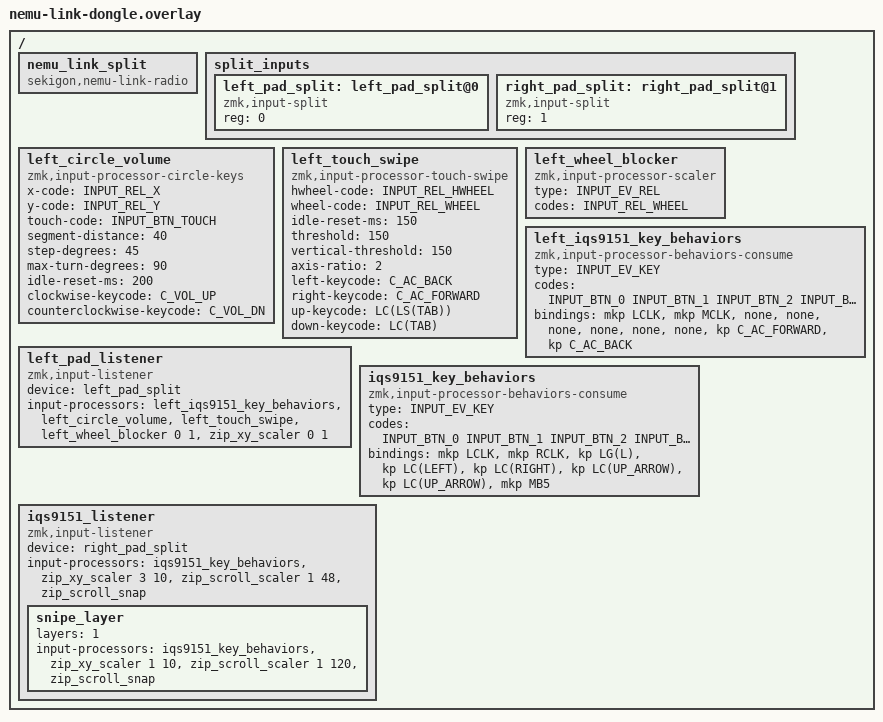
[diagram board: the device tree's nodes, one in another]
/*
 * nemu-link dongle (2.4GHz receiver / split central / USB HID).
 *
 * The dongle has no keys or pads of its own: both halves forward their key
 * positions and raw IQS9151 events, and everything that used to run on the
 * right (BLE central) half runs here: the keymap, combos, and every pad
 * listener / input processor below.
 */
#include <behaviors.dtsi>
#include <scroll-snap.dtsi>
#include <input/processors.dtsi>
#include <dt-bindings/zmk/input_transform.h>
#include <dt-bindings/zmk/keys.h>
#include <dt-bindings/zmk/pointing.h>
#include <zephyr/dt-bindings/input/input-event-codes.h>
#include "../../shields/nickey44a/nickey44a_layouts.dtsi"

/ {
    nemu_link_split {
        compatible = "sekigon,nemu-link-radio";
    };
};

/ {
    split_inputs {
        #address-cells = <1>;
        #size-cells = <0>;

        /* Left half (PERIPHERAL_ID 0) pad. */
        left_pad_split: left_pad_split@0 {
            compatible = "zmk,input-split";
            reg = <0>;
        };

        /* Right half (PERIPHERAL_ID 1) pad. */
        right_pad_split: right_pad_split@1 {
            compatible = "zmk,input-split";
            reg = <1>;
        };
    };

    /*
     * Left pad: one-finger circular motion changes the volume (clockwise =
     * up, 45 degrees per step). If the direction feels reversed on hardware,
     * swap the two keycodes.
     */
    left_circle_volume: left_circle_volume {
        compatible = "zmk,input-processor-circle-keys";
        #input-processor-cells = <0>;
        x-code = <INPUT_REL_X>;
        y-code = <INPUT_REL_Y>;
        /* IQS9151 has no TOUCH event; idle-reset-ms delimits strokes. */
        touch-code = <INPUT_BTN_TOUCH>;
        /* Tuned for IQS9151 raw counts; raise if jitter fires steps. */
        segment-distance = <40>;
        step-degrees = <45>;
        max-turn-degrees = <90>;
        idle-reset-ms = <200>;
        clockwise-keycode = <C_VOL_UP>;
        counterclockwise-keycode = <C_VOL_DN>;
    };

    /*
     * Left pad (IQS9151): one browser tab switch per two-finger up/down
     * swipe (Ctrl+Tab = next tab, Ctrl+Shift+Tab = previous tab). The
     * IQS9151 has no TOUCH event, so a WHEEL gap of idle-reset-ms starts a
     * new swipe. Horizontal Back/Forward comes from the driver's one-shot
     * 2F swipe (BTN_8/BTN_9) instead, since SCROLL_X is off on the left.
     * If the vertical direction is reversed on hardware, swap the keycodes.
     */
    left_touch_swipe: left_touch_swipe {
        compatible = "zmk,input-processor-touch-swipe";
        #input-processor-cells = <0>;
        hwheel-code = <INPUT_REL_HWHEEL>;
        wheel-code = <INPUT_REL_WHEEL>;
        idle-reset-ms = <150>;
        /* Raw IQS9151 centroid counts after the 50-count scroll start. */
        threshold = <150>;
        vertical-threshold = <150>;
        axis-ratio = <2>;
        left-keycode = <C_AC_BACK>;
        right-keycode = <C_AC_FORWARD>;
        up-keycode = <LC(LS(TAB))>;
        down-keycode = <LC(TAB)>;
    };

    /* Left pad: vertical two-finger motion only switches tabs, never scrolls. */
    left_wheel_blocker: left_wheel_blocker {
        compatible = "zmk,input-processor-scaler";
        #input-processor-cells = <2>;
        type = <INPUT_EV_REL>;
        codes = <INPUT_REL_WHEEL>;
    };

    /*
     * Left pad gesture keys from the IQS9151 driver:
     *   BTN_0 1F tap         -> left click
     *   BTN_1 2F tap         -> middle click
     *   BTN_8 / BTN_9 2F swipe right / left -> Forward / Back
     *   BTN_2..BTN_7 (3F, pinch) are disabled in nickey44a_l.conf and
     *   swallowed here so they never click.
     * If Back/Forward is reversed on hardware, swap the BTN_8/BTN_9 bindings.
     */
    left_iqs9151_key_behaviors: left_iqs9151_key_behaviors {
        compatible = "zmk,input-processor-behaviors-consume";
        #input-processor-cells = <0>;
        type = <INPUT_EV_KEY>;
        codes = <INPUT_BTN_0 INPUT_BTN_1 INPUT_BTN_2 INPUT_BTN_3 INPUT_BTN_4
                 INPUT_BTN_5 INPUT_BTN_6 INPUT_BTN_7 INPUT_BTN_8 INPUT_BTN_9>;
        bindings = <&mkp LCLK>, <&mkp MCLK>, <&none>, <&none>, <&none>,
                   <&none>, <&none>, <&none>, <&kp C_AC_FORWARD>, <&kp C_AC_BACK>;
    };

    left_pad_listener: left_pad_listener {
        compatible = "zmk,input-listener";
        device = <&left_pad_split>;
        /*
         * Map gesture keys, observe the circle (volume), turn WHEEL into tab
         * switching, then zero WHEEL and X/Y: the left pad never moves the
         * cursor or scrolls.
         */
        input-processors = <&left_iqs9151_key_behaviors>, <&left_circle_volume>,
                           <&left_touch_swipe>, <&left_wheel_blocker 0 1>,
                           <&zip_xy_scaler 0 1>;
    };

    /*
     * Right pad: LalaPad Gen2 IQS9151 (same gesture mapping as LalaPad Gen2's
     * Mac layer, right side). The driver reports gestures as INPUT_BTN_x key
     * events; they are bound directly to behaviors here instead of
     * LalaPad's virtual key positions (&tp_to_pos).
     *   BTN_0 1F tap / hold       -> left click (drag)
     *   BTN_1 2F tap              -> right click
     *   BTN_2 3F tap              -> Launchpad (LG(L), same as &launch)
     *   BTN_3 / BTN_4 3F swipe L/R -> previous / next desktop (LC(LEFT) / LC(RIGHT))
     *   BTN_5 / BTN_6 3F swipe U/D -> Mission Control (LC(UP), same as &mission)
     *   BTN_7 2F pinch            -> MB5 held + wheel
     */
    iqs9151_key_behaviors: iqs9151_key_behaviors {
        compatible = "zmk,input-processor-behaviors-consume";
        #input-processor-cells = <0>;
        type = <INPUT_EV_KEY>;
        codes = <INPUT_BTN_0 INPUT_BTN_1 INPUT_BTN_2 INPUT_BTN_3
                 INPUT_BTN_4 INPUT_BTN_5 INPUT_BTN_6 INPUT_BTN_7>;
        bindings = <&mkp LCLK>, <&mkp RCLK>, <&kp LG(L)>, <&kp LC(LEFT)>,
                   <&kp LC(RIGHT)>, <&kp LC(UP_ARROW)>, <&kp LC(UP_ARROW)>, <&mkp MB5>;
    };

    iqs9151_listener: iqs9151_listener {
        compatible = "zmk,input-listener";
        device = <&right_pad_split>;
        input-processors = <&iqs9151_key_behaviors>,
                           <&zip_xy_scaler 3 10>,
                           <&zip_scroll_scaler 1 48>,
                           <&zip_scroll_snap>;

        snipe_layer {
            layers = <1>;
            input-processors = <&iqs9151_key_behaviors>,
                               <&zip_xy_scaler 1 10>,
                               <&zip_scroll_scaler 1 120>,
                               <&zip_scroll_snap>;
        };
    };
};
